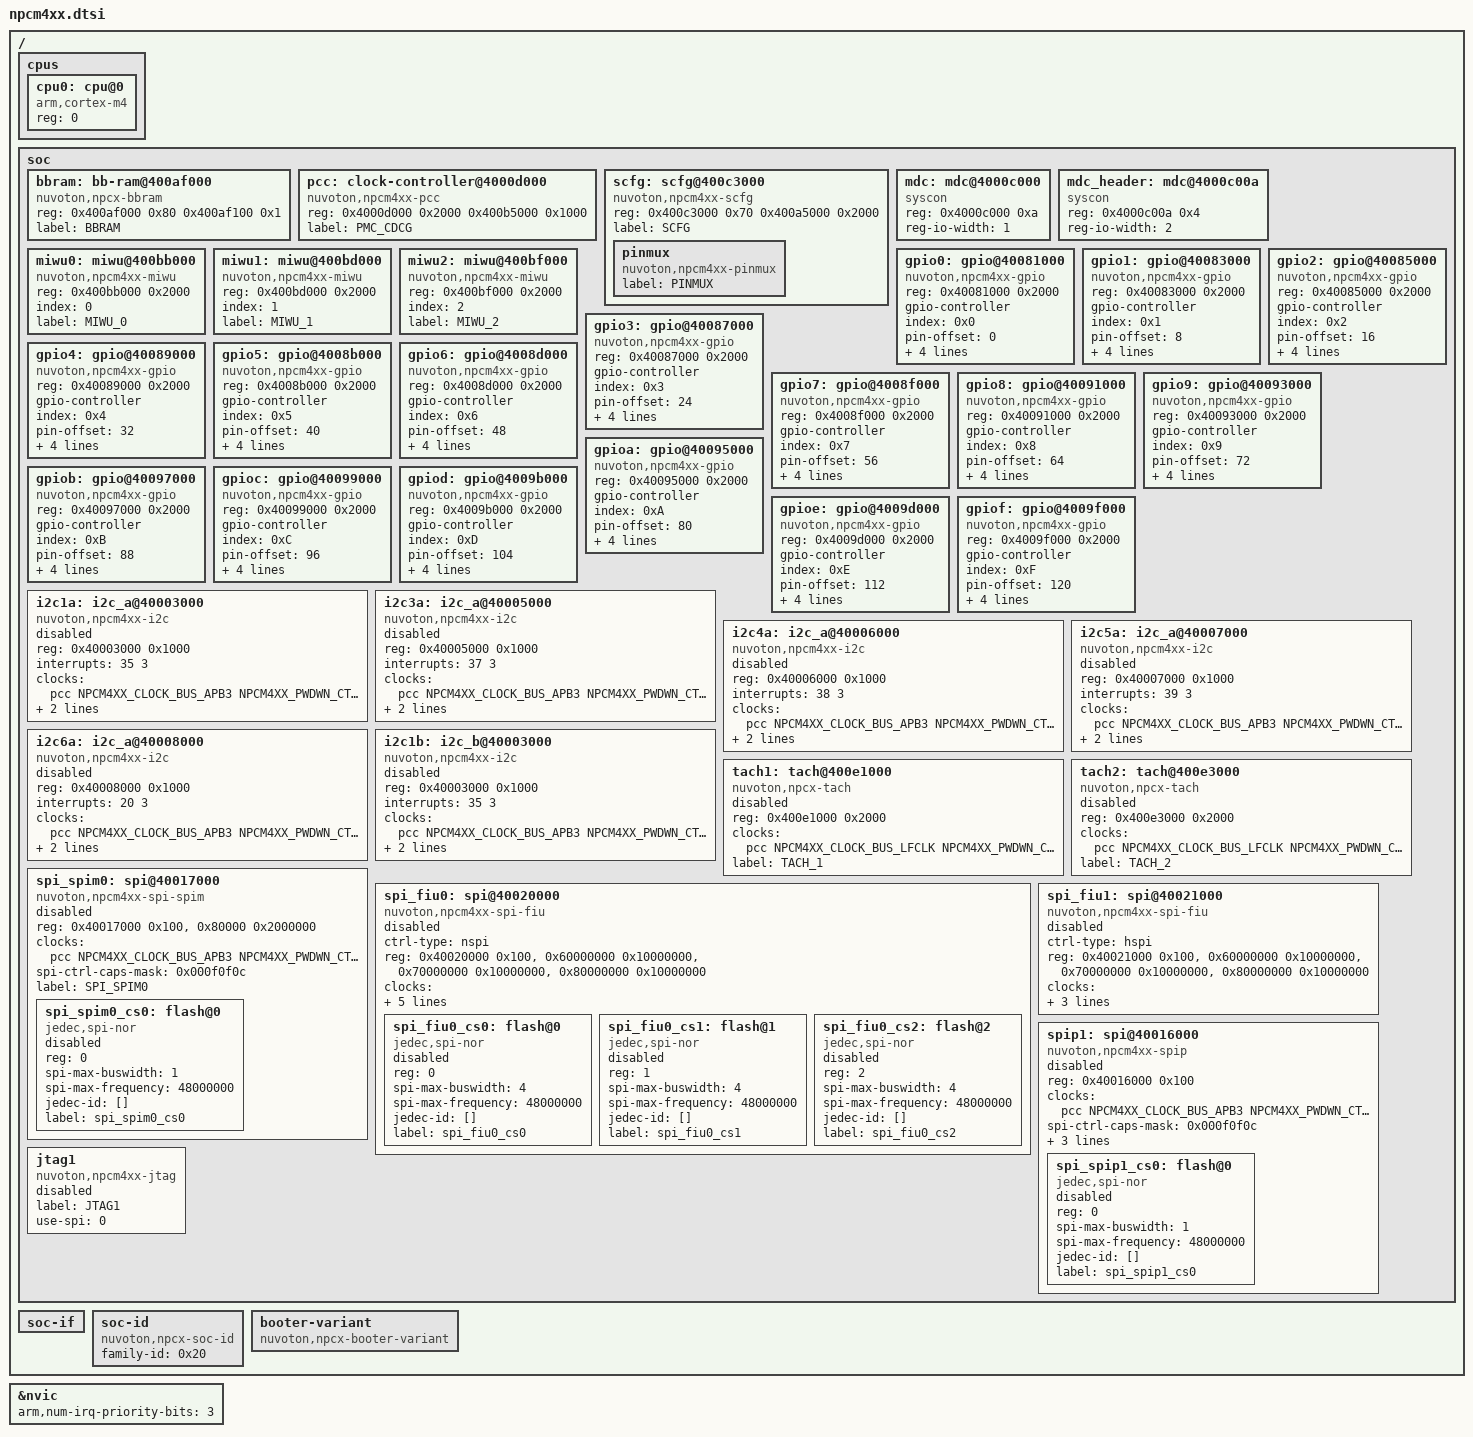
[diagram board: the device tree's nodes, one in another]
/*
 * Copyright (c) 2021 Nuvoton Technology Corporation.
 *
 * SPDX-License-Identifier: Apache-2.0
 */

#include <arm/armv7-m.dtsi>

/* Macros for device tree declarations of npcm4xx soc family */
#include <dt-bindings/clock/npcm4xx_clock.h>
#include <dt-bindings/espi/npcm4xx_espi.h>
#include <dt-bindings/gpio/gpio.h>
#include <dt-bindings/i2c/i2c.h>
#include <dt-bindings/pwm/pwm.h>
#include <dt-bindings/sensor/npcx_tach.h>
#include <freq.h>

/* NPCM4XX series mapping table between MIWU wui bits and source device */
#include "npcm4xx/npcm4xx-miwus-wui-map.dtsi"
/* NPCM4XX series mapping table between MIWU groups and interrupts */
#include "npcm4xx/npcm4xx-miwus-int-map.dtsi"
/* NPCM4XX series eSPI VW mapping table */
#include "npcm4xx/npcm4xx-espi-vws-map.dtsi"


/ {
	cpus {
		#address-cells = <1>;
		#size-cells = <0>;

		cpu0: cpu@0 {
			device_type = "cpu";
			compatible = "arm,cortex-m4";
			reg = <0>;
		};
	};

	soc {
		bbram: bb-ram@400af000 {
			compatible = "nuvoton,npcx-bbram";
			reg = <0x400af000 0x80
			       0x400af100 0x1>;
			reg-names = "memory", "status";
			label = "BBRAM";
		};

		pcc: clock-controller@4000d000 {
			compatible = "nuvoton,npcm4xx-pcc";
			/* Cells for bus type, clock control reg and bit */
			#clock-cells = <3>;
			/* First reg region is Power Management Controller */
			/* Second reg region is Core Domain Clock Generator */
			reg = <0x4000d000 0x2000
			       0x400b5000 0x1000>;
			reg-names = "pmc", "cdcg";
			label = "PMC_CDCG";
		};

		scfg: scfg@400c3000 {
			compatible = "nuvoton,npcm4xx-scfg";
			/* First reg region is System Configuration Device */
			/* Second reg region is System Glue Device */
			reg = <0x400c3000 0x70
			       0x400a5000 0x2000>;
			reg-names = "scfg", "glue";
			#alt-cells = <3>;
			#lvol-cells = <4>;
			label = "SCFG";

			pinmux: pinmux {
				compatible = "nuvoton,npcm4xx-pinmux";
				label = "PINMUX";
			};
		};

		mdc: mdc@4000c000 {
			compatible = "syscon";
			reg = <0x4000c000 0xa>;
			reg-io-width = <1>;
		};

		mdc_header: mdc@4000c00a {
			compatible = "syscon";
			reg = <0x4000c00a 0x4>;
			reg-io-width = <2>;
		};

		miwu0: miwu@400bb000 {
			compatible = "nuvoton,npcm4xx-miwu";
			reg = <0x400bb000 0x2000>;
			index = <0>;
			#miwu-cells = <2>;
			label="MIWU_0";
		};

		miwu1: miwu@400bd000 {
			compatible = "nuvoton,npcm4xx-miwu";
			reg = <0x400bd000 0x2000>;
			index = <1>;
			#miwu-cells = <2>;
			label="MIWU_1";
		};

		miwu2: miwu@400bf000 {
			compatible = "nuvoton,npcm4xx-miwu";
			reg = <0x400bf000 0x2000>;
			index = <2>;
			#miwu-cells = <2>;
			label="MIWU_2";
		};

		gpio0: gpio@40081000 {
			compatible = "nuvoton,npcm4xx-gpio";
			reg = <0x40081000 0x2000>;
			gpio-controller;
			index = <0x0>;
			pin-offset = <0>;
			wui-maps = <&wui_io00 &wui_io01 &wui_io02 &wui_io03
				    &wui_io04 &wui_io05 &wui_io06 &wui_io07>;
			#gpio-cells=<2>;
			label="GPIO_0";
		};

		gpio1: gpio@40083000 {
			compatible = "nuvoton,npcm4xx-gpio";
			reg = <0x40083000 0x2000>;
			gpio-controller;
			index = <0x1>;
			pin-offset = <8>;
			wui-maps = <&wui_io10 &wui_io11 &wui_io12 &wui_io13
				    &wui_io14 &wui_io15 &wui_io16 &wui_io17>;
			#gpio-cells=<2>;
			label="GPIO_1";
		};

		gpio2: gpio@40085000 {
			compatible = "nuvoton,npcm4xx-gpio";
			reg = <0x40085000 0x2000>;
			gpio-controller;
			index = <0x2>;
			pin-offset = <16>;
			wui-maps = <&wui_io20 &wui_io21 &wui_io22 &wui_io23
				    &wui_io24 &wui_io25 &wui_io26 &wui_io27>;
			#gpio-cells=<2>;
			label="GPIO_2";
		};

		gpio3: gpio@40087000 {
			compatible = "nuvoton,npcm4xx-gpio";
			reg = <0x40087000 0x2000>;
			gpio-controller;
			index = <0x3>;
			pin-offset = <24>;
			wui-maps = <&wui_io30 &wui_io31 &wui_io32 &wui_io33
				    &wui_io34 &wui_io35 &wui_io36 &wui_io37>;
			#gpio-cells=<2>;
			label="GPIO_3";
		};

		gpio4: gpio@40089000 {
			compatible = "nuvoton,npcm4xx-gpio";
			reg = <0x40089000 0x2000>;
			gpio-controller;
			index = <0x4>;
			pin-offset = <32>;
			wui-maps = <&wui_io40 &wui_io41 &wui_io42 &wui_io43
				    &wui_io44 &wui_io45 &wui_io46 &wui_io47>;
			#gpio-cells=<2>;
			label="GPIO_4";
		};

		gpio5: gpio@4008b000 {
			compatible = "nuvoton,npcm4xx-gpio";
			reg = <0x4008b000 0x2000>;
			gpio-controller;
			index = <0x5>;
			pin-offset = <40>;
			wui-maps = <&wui_io50 &wui_io51 &wui_io52 &wui_io53
				    &wui_io54 &wui_io55 &wui_io56 &wui_io57>;
			#gpio-cells=<2>;
			label="GPIO_5";
		};

		gpio6: gpio@4008d000 {
			compatible = "nuvoton,npcm4xx-gpio";
			reg = <0x4008d000 0x2000>;
			gpio-controller;
			index = <0x6>;
			pin-offset = <48>;
			wui-maps = <&wui_io60 &wui_io61 &wui_io62 &wui_io63
				    &wui_io64 &wui_io65 &wui_io66 &wui_io67>;
			#gpio-cells=<2>;
			label="GPIO_6";
		};

		gpio7: gpio@4008f000 {
			compatible = "nuvoton,npcm4xx-gpio";
			reg = <0x4008f000 0x2000>;
			gpio-controller;
			index = <0x7>;
			pin-offset = <56>;
			wui-maps = <&wui_io70 &wui_io71 &wui_io72 &wui_io73
				    &wui_io74 &wui_io75 &wui_io76 &wui_io77>;
			#gpio-cells=<2>;
			label="GPIO_7";
		};

		gpio8: gpio@40091000 {
			compatible = "nuvoton,npcm4xx-gpio";
			reg = <0x40091000 0x2000>;
			gpio-controller;
			index = <0x8>;
			pin-offset = <64>;
			wui-maps = <&wui_io80 &wui_io81 &wui_io82 &wui_io83
				    &wui_io84 &wui_io85 &wui_io86 &wui_io87>;
			#gpio-cells=<2>;
			label="GPIO_8";
		};

		gpio9: gpio@40093000 {
			compatible = "nuvoton,npcm4xx-gpio";
			reg = <0x40093000 0x2000>;
			gpio-controller;
			index = <0x9>;
			pin-offset = <72>;
			wui-maps = <&wui_io90 &wui_io91 &wui_io92 &wui_io93
				    &wui_io94 &wui_io95 &wui_io96 &wui_io97>;
			#gpio-cells=<2>;
			label="GPIO_9";
		};

		gpioa: gpio@40095000 {
			compatible = "nuvoton,npcm4xx-gpio";
			reg = <0x40095000 0x2000>;
			gpio-controller;
			index = <0xA>;
			pin-offset = <80>;
			wui-maps = <&wui_ioa0 &wui_ioa1 &wui_ioa2 &wui_ioa3
				    &wui_ioa4 &wui_ioa5 &wui_ioa6 &wui_ioa7>;
			#gpio-cells=<2>;
			label="GPIO_A";
		};

		gpiob: gpio@40097000 {
			compatible = "nuvoton,npcm4xx-gpio";
			reg = <0x40097000 0x2000>;
			gpio-controller;
			index = <0xB>;
			pin-offset = <88>;
			wui-maps = <&wui_iob0 &wui_iob1 &wui_iob2 &wui_iob3
				    &wui_iob4 &wui_iob5 &wui_iob6 &wui_iob7>;
			#gpio-cells=<2>;
			label="GPIO_B";
		};

		gpioc: gpio@40099000 {
			compatible = "nuvoton,npcm4xx-gpio";
			reg = <0x40099000 0x2000>;
			gpio-controller;
			index = <0xC>;
			pin-offset = <96>;
			wui-maps = <&wui_ioc0 &wui_ioc1 &wui_ioc2 &wui_ioc3
				    &wui_ioc4 &wui_ioc5 &wui_ioc6 &wui_ioc7>;
			#gpio-cells=<2>;
			label="GPIO_C";
		};

		gpiod: gpio@4009b000 {
			compatible = "nuvoton,npcm4xx-gpio";
			reg = <0x4009b000 0x2000>;
			gpio-controller;
			index = <0xD>;
			pin-offset = <104>;
			wui-maps = <&wui_iod0 &wui_iod1 &wui_iod2 &wui_iod3
				    &wui_iod4 &wui_iod5 &wui_iod6 &wui_iod7>;
			#gpio-cells=<2>;
			label="GPIO_D";
		};

		gpioe: gpio@4009d000 {
			compatible = "nuvoton,npcm4xx-gpio";
			reg = <0x4009d000 0x2000>;
			gpio-controller;
			index = <0xE>;
			pin-offset = <112>;
			wui-maps = <&wui_ioe0 &wui_ioe1 &wui_ioe2 &wui_ioe3
				    &wui_ioe4 &wui_ioe5 &wui_ioe6 &wui_none>;
			#gpio-cells=<2>;
			label="GPIO_E";
		};

		gpiof: gpio@4009f000 {
			compatible = "nuvoton,npcm4xx-gpio";
			reg = <0x4009f000 0x2000>;
			gpio-controller;
			index = <0xF>;
			pin-offset = <120>;
			wui-maps = <&wui_iof0 &wui_iof1 &wui_iof2 &wui_iof3
				    &wui_none &wui_none &wui_none &wui_none>;
			#gpio-cells=<2>;
			label="GPIO_F";
		};

		i2c1a: i2c_a@40003000 {
			compatible = "nuvoton,npcm4xx-i2c";
			#address-cells = <1>;
			#size-cells = <0>;
			reg = <0x40003000 0x1000>;
			interrupts = <35 3>;
			clocks = <&pcc NPCM4XX_CLOCK_BUS_APB3 NPCM4XX_PWDWN_CTL3 0>;
			pinctrl-0 = <&pinctrl_i2c1a_default>;
			label = "I2C_0";
			status = "disabled";
		};

		i2c3a: i2c_a@40005000 {
			compatible = "nuvoton,npcm4xx-i2c";
			#address-cells = <1>;
			#size-cells = <0>;
			reg = <0x40005000 0x1000>;
			interrupts = <37 3>;
			clocks = <&pcc NPCM4XX_CLOCK_BUS_APB3 NPCM4XX_PWDWN_CTL3 2>;
			pinctrl-0 = <&pinctrl_i2c3a_default>;
			label = "I2C_1";
			status = "disabled";
		};

		i2c4a: i2c_a@40006000 {
			compatible = "nuvoton,npcm4xx-i2c";
			#address-cells = <1>;
			#size-cells = <0>;
			reg = <0x40006000 0x1000>;
			interrupts = <38 3>;
			clocks = <&pcc NPCM4XX_CLOCK_BUS_APB3 NPCM4XX_PWDWN_CTL3 3>;
			pinctrl-0 = <&pinctrl_i2c4a_default>;
			label = "I2C_2";
			status = "disabled";
		};

		i2c5a: i2c_a@40007000 {
			compatible = "nuvoton,npcm4xx-i2c";
			#address-cells = <1>;
			#size-cells = <0>;
			reg = <0x40007000 0x1000>;
			interrupts = <39 3>;
			clocks = <&pcc NPCM4XX_CLOCK_BUS_APB3 NPCM4XX_PWDWN_CTL3 4>;
			pinctrl-0 = <&pinctrl_i2c5a_default>;
			label = "I2C_3";
			status = "disabled";
		};

		i2c6a: i2c_a@40008000 {
			compatible = "nuvoton,npcm4xx-i2c";
			#address-cells = <1>;
			#size-cells = <0>;
			reg = <0x40008000 0x1000>;
			interrupts = <20 3>;
			clocks = <&pcc NPCM4XX_CLOCK_BUS_APB3 NPCM4XX_PWDWN_CTL3 5>;
			pinctrl-0 = <&pinctrl_i2c6a_default>;
			label = "I2C_4";
			status = "disabled";
		};

		i2c1b: i2c_b@40003000 {
			compatible = "nuvoton,npcm4xx-i2c";
			#address-cells = <1>;
			#size-cells = <0>;
			reg = <0x40003000 0x1000>;
			interrupts = <35 3>;
			clocks = <&pcc NPCM4XX_CLOCK_BUS_APB3 NPCM4XX_PWDWN_CTL3 0>;
			pinctrl-0 = <&pinctrl_i2c1b_default>;
			label = "I2C_0";
			status = "disabled";
		};

		tach1: tach@400e1000 {
			compatible = "nuvoton,npcx-tach";
			reg = <0x400e1000 0x2000>;
			clocks = <&pcc NPCM4XX_CLOCK_BUS_LFCLK NPCM4XX_PWDWN_CTL1 5>;
			label = "TACH_1";
			status = "disabled";
		};

		tach2: tach@400e3000 {
			compatible = "nuvoton,npcx-tach";
			reg = <0x400e3000 0x2000>;
			clocks = <&pcc NPCM4XX_CLOCK_BUS_LFCLK NPCM4XX_PWDWN_CTL1 6>;
			label = "TACH_2";
			status = "disabled";
		};

		spi_spim0: spi@40017000 {
			compatible = "nuvoton,npcm4xx-spi-spim";
			#address-cells = <1>;
			#size-cells = <0>;
			reg-names = "ctrl_reg", "spi_mmap";
			reg = <0x40017000 0x100>, <0x80000 0x2000000>;
			clocks = <&pcc NPCM4XX_CLOCK_BUS_APB3 NPCM4XX_PWDWN_CTL1 0>;
			spi-ctrl-caps-mask = <0x000f0f0c>;
			label = "SPI_SPIM0";
			status = "disabled";

			spi_spim0_cs0: flash@0 {
				compatible ="jedec,spi-nor";
				reg = <0>;
				spi-max-buswidth = <1>;
				spi-max-frequency = <48000000>;
				jedec-id = [];
				label = "spi_spim0_cs0";
				status = "disabled";
			};
		};

		spi_fiu0: spi@40020000 {
			compatible = "nuvoton,npcm4xx-spi-fiu";
			#address-cells = <1>;
			#size-cells = <0>;
			ctrl-type = "nspi";
			reg-names = "ctrl_reg", "backup_mmap", "share_mmap", "private_mmap";
			reg = <0x40020000 0x100>, <0x60000000 0x10000000>,
				<0x70000000 0x10000000>, <0x80000000 0x10000000>;
			clocks = <&pcc NPCM4XX_CLOCK_BUS_APB3 NPCM4XX_PWDWN_CTL1 2>;
			pinctrl-0 = <&pinctrl_shd_spi_default &pinctrl_shd_spi_quad>;
			spi-ctrl-caps-mask = <0x000c0f0c>;
			label = "SPI_FIU0";
			status = "disabled";

			spi_fiu0_cs0: flash@0 {
				compatible ="jedec,spi-nor";
				/* slave */
				reg = <0>;
				spi-max-buswidth = <4>;
				spi-max-frequency = <48000000>;
				jedec-id = [];
				label = "spi_fiu0_cs0";
				status = "disabled";
			};

			spi_fiu0_cs1: flash@1 {
				compatible ="jedec,spi-nor";
				/* slave */
				reg = <1>;
				spi-max-buswidth = <4>;
				spi-max-frequency = <48000000>;
				jedec-id = [];
				label = "spi_fiu0_cs1";
				status = "disabled";
			};

			spi_fiu0_cs2: flash@2 {
				compatible ="jedec,spi-nor";
				/* slave */
				reg = <2>;
				spi-max-buswidth = <4>;
				spi-max-frequency = <48000000>;
				jedec-id = [];
				label = "spi_fiu0_cs2";
				status = "disabled";
                        };

		};

		spi_fiu1: spi@40021000 {
			compatible = "nuvoton,npcm4xx-spi-fiu";
			#address-cells = <1>;
			#size-cells = <0>;
			ctrl-type = "hspi";
			reg-names = "ctrl_reg", "backup_mmap", "share_mmap", "private_mmap";
                        reg = <0x40021000 0x100>, <0x60000000 0x10000000>,
				<0x70000000 0x10000000>, <0x80000000 0x10000000>;
			clocks = <&pcc NPCM4XX_CLOCK_BUS_APB3 NPCM4XX_PWDWN_CTL1 2>;
			spi-ctrl-caps-mask = <0x000c0f0c>;
			label = "SPI_FIU1";
			status = "disabled";
		};

		spip1: spi@40016000 {
			compatible = "nuvoton,npcm4xx-spip";
			#address-cells = <1>;
			#size-cells = <0>;
			reg = <0x40016000 0x100>;
			clocks = <&pcc NPCM4XX_CLOCK_BUS_APB3 NPCM4XX_PWDWN_CTL4 7>;
			spi-ctrl-caps-mask = <0x000f0f0c>;
			pinctrl-0 = <&pinctrl_spip1_default &pinctrl_spip1_quad>;
			label = "SPIP";
			status = "disabled";

			spi_spip1_cs0: flash@0 {
				compatible ="jedec,spi-nor";
				/* slave */
				reg = <0>;
				spi-max-buswidth = <1>;
				spi-max-frequency = <48000000>;
				jedec-id = [];
				label = "spi_spip1_cs0";
				status = "disabled";
			};
		};

		jtag1: jtag1 {
			compatible = "nuvoton,npcm4xx-jtag";
			label = "JTAG1";
			use-spi = <0>;
			status = "disabled";
		};

	};

	soc-if {
		/* Soc specific peripheral interface phandles which don't contain
		 * 'reg' prop. Please overwrite 'status' prop. to 'okay' if you
		 * want to switch the interface from io to specific peripheral.
		 */
	};

	soc-id {
		compatible = "nuvoton,npcx-soc-id";
		family-id = <0x20>;
	};

	booter-variant {
		compatible = "nuvoton,npcx-booter-variant";
	};
};

&nvic {
	arm,num-irq-priority-bits = <3>;
};
